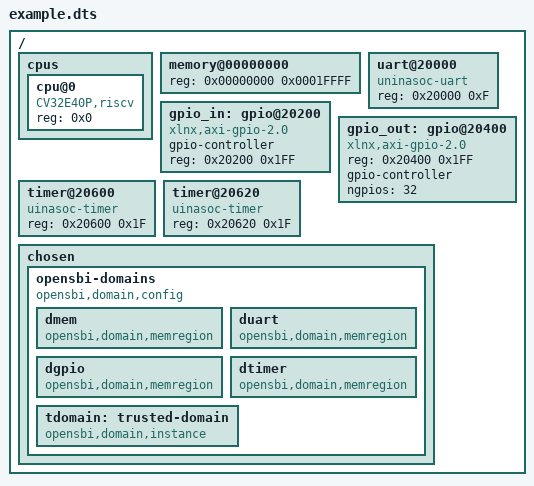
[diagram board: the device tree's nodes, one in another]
// all names are compliant with 2.2.2. Generic Names Recommendation

/dts-v1/;

/ {
    cpus {
        #address-cells = <1>;
        #size-cells = <0>;

        cpu@0{
            device_type = "cpu";
            reg = <0x0>;
            compatible = "CV32E40P,riscv";
        };
    };

    memory@00000000{
        device_type = "memory";
        reg = <0x00000000 0x0001FFFF>;
    };

    uart@20000{
        compatible = "uninasoc-uart";
        reg = <0x20000 0xF>;
    };

    gpio_in: gpio@20200{
        compatible = "xlnx,axi-gpio-2.0", "xlnx,xps-gpio-1.00.a";
        gpio-controller;
        reg = <0x20200 0x1FF>;
    };

    gpio_out: gpio@20400{
        #gpio-cells=<2>; //TODO: capire come configurare
        compatible = "xlnx,axi-gpio-2.0", "xlnx,xps-gpio-1.00.a";
        reg = <0x20400 0x1FF>;
        gpio-controller;
        ngpios = <32>;
    };

    timer@20600{
        compatible = "uinasoc-timer"; //andrebbe messo un altro campo ,vendor nel caso in cui il timer
                                      //abbia un version number
        reg = <0x20600 0x1F>;
    };

    timer@20620{
        compatible = "uinasoc-timer"; //andrebbe messo un altro campo ,vendor nel caso in cui il timer
                                      //abbia un version number
        reg = <0x20620 0x1F>;
    };

    //section related to domain specification
    chosen{
        opensbi-domains {
            //define a domain configuration
            compatible = "opensbi,domain,config";
            //define all the peripherals above as domain memory regions (see opensbi domain specification)
            dmem: dmem{
                compatible = "opensbi,domain,memregion";
            };

            duart: duart{
                compatible = "opensbi,domain,memregion";
            };

            dgpio: dgpio{
                compatible = "opensbi,domain,memregion";
            };

            dgpio: dgpio{
                compatible = "opensbi,domain,memregion";
            };

            dtimer: dtimer {
                compatible = "opensbi,domain,memregion";
            };

            dtimer: dtimer {
                compatible = "opensbi,domain,memregion";
            };

            //define the actual domain instance
            tdomain: trusted-domain {
                compatible = "opensbi,domain,instance";
            };

            /*TODO: compilare i restanti campi*/
        };
    };
};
